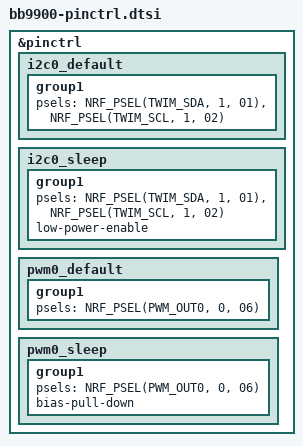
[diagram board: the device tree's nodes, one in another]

/*
 * Copyright (c) 2023 ZitaoTech
 * SPDX-License-Identifier: MIT
 */

&pinctrl {
    i2c0_default: i2c0_default {
        group1 {
            psels = <NRF_PSEL(TWIM_SDA, 1, 01)>,
                <NRF_PSEL(TWIM_SCL, 1, 02)>;
        };
    };

    i2c0_sleep: i2c0_sleep {
        group1 {
            psels = <NRF_PSEL(TWIM_SDA, 1, 01)>,
                <NRF_PSEL(TWIM_SCL, 1, 02)>;
            low-power-enable;
        };
    };

    pwm0_default: pwm0_default {
        group1 {
            psels = <NRF_PSEL(PWM_OUT0, 0, 06)>; // Backlight
        };
    };

    pwm0_sleep: pwm0_sleep {
        group1 {
            psels = <NRF_PSEL(PWM_OUT0, 0, 06)>;
            bias-pull-down;
        };
    };
};
